# M3351 register map
File version: 1.0
Registers are 32-bit, read-write, reset 0x0 unless marked. A register's access mark holds for its fields unless they carry their own. Offsets are from the block's base; [hi:lo] are bit positions; {n}, {i} and the like mark numbered series; 'fields as' and 'values as' point back to an identical list.

## NVIC — NVIC Register Map
Base 0xE000E100
{0x0+4i} NVIC_ISER{i} (i=0..3) — IRQ0 ~ IRQ138 Set-enable Control Register
  [31:0] SETENA — Interrupt Set Enable Bit. The NVIC_ISER0-NVIC_ISER3 registers enable interrupts, and show which interrupts are enabled. Write Operation:
    0=No effect. Interrupt Disabled; 1=Interrupt Enabled
{0x80+4i} NVIC_ICER{i} (i=0..3) — IRQ0 ~ IRQ138 Clear-enable Control Register
  [31:0] CALENA — Interrupt Clear Enable Bit. The NVIC_ICER0-NVIC_ICER3 registers disable interrupts, and show which interrupts are enabled. Write Operation:
    0=No effect. Interrupt Disabled; 1=Interrupt Disabled. Interrupt Enabled
{0x100+4i} NVIC_ISPR{i} (i=0..3) — IRQ0 ~ IRQ138 Set-pending Control Register
  [31:0] SETPEND — Interrupt Set-pending. The NVIC_ISPR0-NVIC_ISPR3 registers force interrupts into the pending state, and show which interrupts are pending. Write Operation:
    0=No effect. Interrupt is not pending; 1=Changes interrupt state to pending. Interrupt is pending
{0x180+4i} NVIC_ICPR{i} (i=0..3) — IRQ0 ~ IRQ138 Clear-pending Control Register
  [31:0] CALPEND — Interrupt Clear-pending. The NVIC_ICPR0-NVIC_ICPR3 registers remove the pending state from interrupts, and show which interrupts are pending. Write Operation:
    0=No effect. Interrupt is not pending; 1=Removes pending state an interrupt. Interrupt is pending
{0x200+4i} NVIC_IABR{i} (i=0..3) — IRQ0 ~ IRQ138 Active Bit Register
  [31:0] ACTIVE — Interrupt Active Flags. The NVIC_IABR0-NVIC_IABR3 registers indicate which interrupts are active.
    0=Interrupt not active; 1=Interrupt active
{0x280+4i} NVIC_ITNS{i} (i=0..3) — IRQ0 ~ IRQ138 Target Bit Register
  [31:0] TARGET — Interrupt Target Flags. The NVIC_ITNS0-NVIC_ITNS3 registers indicate and allows modification of the target security state.
    0=Interrupt targets secure state; 1=Interrupt targets non secure state
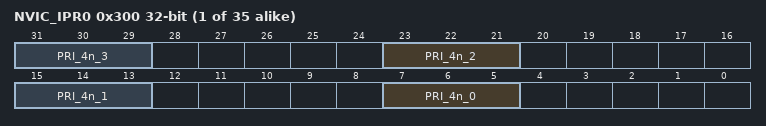
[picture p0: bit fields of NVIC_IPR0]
{0x300+4i} NVIC_IPR{i} (i=0..34) — IRQ0 ~ IRQ138 Priority Control Register
  [8n+7:8n+5] PRI_4n_{n} (n=0..3) — Priority of IRQ_4n+{n} '0' denotes the highest priority and '7' denotes the lowest priority.
0xE00 STIR wo — Software Trigger Interrupt Registers
  [8:0] INTID — Interrupt ID (Write Only). Write to the STIR To Generate An Interrupt from Software. When the USERSETMPEND bit in the CCR is set to 1, unprivileged software can access the STIR. Number of valid Interrupt ID refers to Table 6.29. For example, a value of 0x03 specifies interrupt IRQ3.

## TRNG — TRNG Register Map
Base 0x400B9000
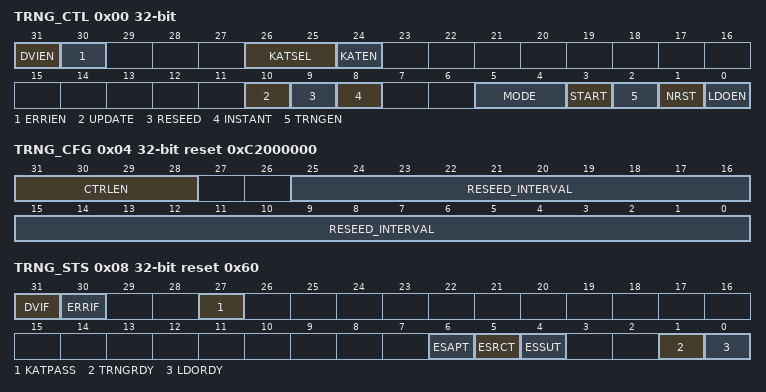
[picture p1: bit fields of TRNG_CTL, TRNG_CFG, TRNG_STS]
0x00 TRNG_CTL — TRNG Control Register
  [31] DVIEN — Data Valid Interrupt Enable Bit
    0=Interrupt Disabled; 1=Interrupt Enabled
  [30] ERRIEN — TRNG Error Interrupt Enable Bit
    0=Error interrupt Disabled; 1=Error interrupt Enabled
  [26:25] KATSEL — CTR_DRBG Known Answer Test Selection
    0=Instantiation testing; 1=Reseed testing; 2=Generation testing
  [24] KATEN — CTR_DRBG Known Answer Test Enable Bit. Note: Do not enable START and KATEN at the same time.
    0=Disabled; 1=Enabled
  [10] UPDATE — CTR_DRBG User Manual Update Function
    0=No effect; 1=Enable CTR_DRBG update function
  [9] RESEED — CTR_DRBG User Manual Reseed Function
    0=No effect; 1=Enable CTR_DRBG reseed function
  [8] INSTANT — CTR_DRBG User Manual Instant Function
    0=No effect; 1=Enable CTR_DRBG instant function
  [5:4] MODE — Random Bit Generator Output Selection
    1=Output data is from NRBG (128-bits); 2=Output data is from DRBG (128-bits)
  [3] START — True Random Number Generator Start. Note: Do not enable START and KATEN at the same time. This bit is always 0 when it is read back.
    0=No effect; 1=Start TRNG
  [2] TRNGEN — True Random Number Generator Macro Enable Bit
    0=TRNG macro Disabled; 1=TRNG macro Enabled
  [1] NRST — Negative-edge Trigger Reset
    0=Keep reset; 1=No reset
  [0] LDOEN — LDO Enable Bit
    0=LDO Disabled; 1=LDO Enabled
0x04 TRNG_CFG reset 0xC2000000 — TRNG Configure Register
  [31:28] CTRLEN — CTR_DRBG Bits Length Per Request
  [25:0] RESEED_INTERVAL — Reseed Interval. Maximum number of requests between reseeds. The value is 1 ~ 225 .
0x08 TRNG_STS ro reset 0x60 — TRNG Status Register
  [31] DVIF — Data Valid Interrupt Flag. Note: This bit is cleared to '0' by reading TRNG_DATA0 ~ TRNG_DATA3.
    0=Data is invalid; 1=Data is valid. A valid random number can be read form TRNG_DATAx
  [30] ERRIF — TRNG Error Interrupt Flag
    0=No TRNG error; 1=TRNGRDY became '0' for a while, TRNG error interrupt
  [27] KATPASS — CTR_DRBG Known Answer Test Pass. Note: When users enable KATEN, they can check this bit after DVIF become '1'.
    0=Test fail; 1=Test pass
  [6] ESAPT — Entropy Source Adaptive Proportion Test
    0=Entropy source is still under testing or test fail; 1=Test pass
  [5] ESRCT — Entropy Source Repetition Count Test
    values as ESAPT
  [4] ESSUT — Entropy Source Start-Up Test
    values as ESAPT
  [1] TRNGRDY — TRNG Ready Signal
    0=True random number generator is not ready; 1=True random number generator is ready
  [0] LDORDY — LDO Ready Signal
    0=LDO is not ready; 1=LDO is ready
{0xC+4i} TRNG_DATA{i} ro (i=0..3) — TRNG Data Output Word {i} Register
  [31:0] DATA — True Random Number Generator Data (Read Only). The DATA stores the output data generated by TRNG, it can be read when DVIF become 1 and can be read only once. TRNG_DATA0 stores NRBG word 0 / DRBG word 0. TRNG_DATA1 stores NRBG word 1 / DRBG word 1. TRNG_DATA2 stores NRBG word 2 / DRBG word 2. TRNG_DATA3 stores NRBG word 3 / DRBG word 3.
